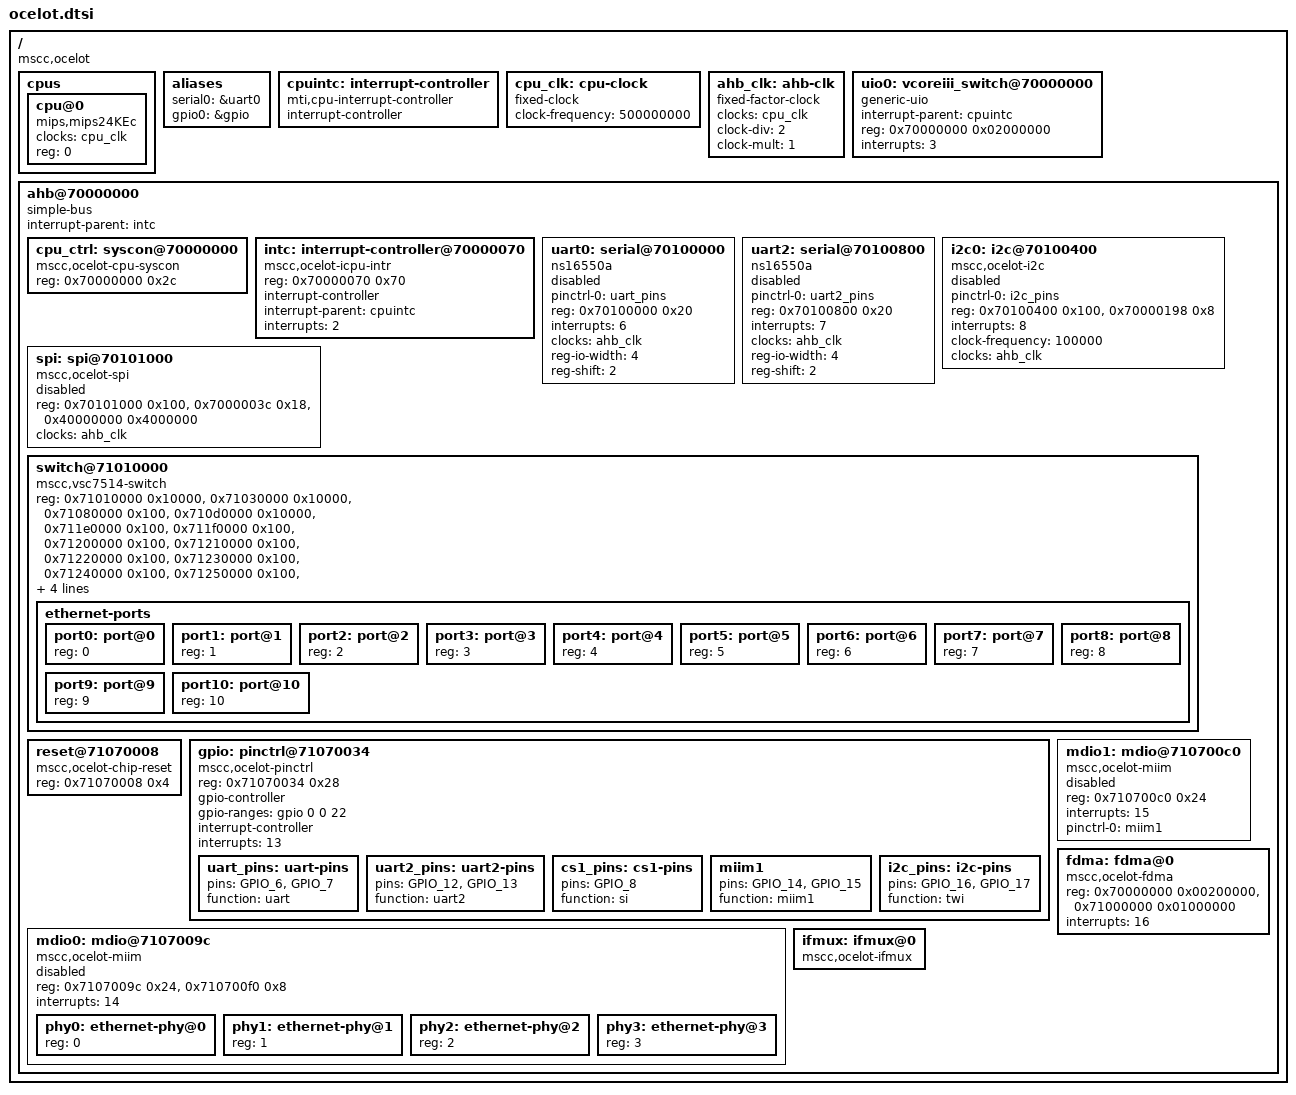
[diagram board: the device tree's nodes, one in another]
// SPDX-License-Identifier: (GPL-2.0 OR MIT)
/* Copyright (c) 2017 Microsemi Corporation */

/ {
	#address-cells = <1>;
	#size-cells = <1>;
	compatible = "mscc,ocelot";

	cpus {
		#address-cells = <1>;
		#size-cells = <0>;

		cpu@0 {
			compatible = "mips,mips24KEc";
			device_type = "cpu";
			clocks = <&cpu_clk>;
			reg = <0>;
		};
	};

	aliases {
		serial0 = &uart0;
		gpio0 = &gpio;
	};

	cpuintc: interrupt-controller {
		#address-cells = <0>;
		#interrupt-cells = <1>;
		interrupt-controller;
		compatible = "mti,cpu-interrupt-controller";
	};

	cpu_clk: cpu-clock {
		compatible = "fixed-clock";
		#clock-cells = <0>;
		clock-frequency = <500000000>;
	};

	ahb_clk: ahb-clk {
		compatible = "fixed-factor-clock";
		#clock-cells = <0>;
		clocks = <&cpu_clk>;
		clock-div = <2>;
		clock-mult = <1>;
	};

	uio0: vcoreiii_switch@70000000 {
		compatible = "generic-uio";
		interrupt-parent = <&cpuintc>;
		reg = <0x70000000 0x02000000>;
		reg-names = "origin1_2";
		interrupts = <3>;
	};

	ahb@70000000 {
		compatible = "simple-bus";
		#address-cells = <1>;
		#size-cells = <1>;
		ranges;

		interrupt-parent = <&intc>;

		cpu_ctrl: syscon@70000000 {
			compatible = "mscc,ocelot-cpu-syscon", "syscon";
			reg = <0x70000000 0x2c>;
		};

		intc: interrupt-controller@70000070 {
			compatible = "mscc,ocelot-icpu-intr";
			reg = <0x70000070 0x70>;
			#interrupt-cells = <1>;
			interrupt-controller;
			interrupt-parent = <&cpuintc>;
			interrupts = <2>;
		};

		uart0: serial@70100000 {
			pinctrl-0 = <&uart_pins>;
			pinctrl-names = "default";
			compatible = "ns16550a";
			reg = <0x70100000 0x20>;
			interrupts = <6>;
			clocks = <&ahb_clk>;
			reg-io-width = <4>;
			reg-shift = <2>;

			status = "disabled";
		};

		uart2: serial@70100800 {
			pinctrl-0 = <&uart2_pins>;
			pinctrl-names = "default";
			compatible = "ns16550a";
			reg = <0x70100800 0x20>;
			interrupts = <7>;
			clocks = <&ahb_clk>;
			reg-io-width = <4>;
			reg-shift = <2>;

			status = "disabled";
		};

		i2c0: i2c@70100400 {
			compatible = "mscc,ocelot-i2c", "snps,designware-i2c";
			status = "disabled";
			pinctrl-0 = <&i2c_pins>;
			pinctrl-names = "default";
			reg = <0x70100400 0x100>, <0x70000198 0x8>;
			#address-cells = <1>;
			#size-cells = <0>;
			interrupts = <8>;
			clock-frequency = <100000>;
			clocks = <&ahb_clk>;
		};

		spi: spi@70101000 {
			compatible = "mscc,ocelot-spi", "snps,dw-apb-ssi";
			#address-cells = <1>;
			#size-cells = <0>;
			reg = <0x70101000 0x100>, <0x7000003c 0x18>, <0x40000000 0x4000000>;
			clocks = <&ahb_clk>;

			status = "disabled";
		};

		switch@71010000 {
			compatible = "mscc,vsc7514-switch";
			reg = <0x71010000 0x10000>,
			      <0x71030000 0x10000>,
			      <0x71080000 0x100>,
			      <0x710d0000 0x10000>,
			      <0x711e0000 0x100>,
			      <0x711f0000 0x100>,
			      <0x71200000 0x100>,
			      <0x71210000 0x100>,
			      <0x71220000 0x100>,
			      <0x71230000 0x100>,
			      <0x71240000 0x100>,
			      <0x71250000 0x100>,
			      <0x71260000 0x100>,
			      <0x71270000 0x100>,
			      <0x71280000 0x100>,
			      <0x71800000 0x80000>,
			      <0x71880000 0x10000>;
			reg-names = "sys", "rew", "qs", "hsio", "port0",
				    "port1", "port2", "port3", "port4", "port5",
				    "port6", "port7", "port8", "port9", "port10",
				    "qsys", "ana";
			interrupts = <21 22>;
			interrupt-names = "xtr", "inj";

			ethernet-ports {
				#address-cells = <1>;
				#size-cells = <0>;

				port0: port@0 {
					reg = <0>;
				};
				port1: port@1 {
					reg = <1>;
				};
				port2: port@2 {
					reg = <2>;
				};
				port3: port@3 {
					reg = <3>;
				};
				port4: port@4 {
					reg = <4>;
				};
				port5: port@5 {
					reg = <5>;
				};
				port6: port@6 {
					reg = <6>;
				};
				port7: port@7 {
					reg = <7>;
				};
				port8: port@8 {
					reg = <8>;
				};
				port9: port@9 {
					reg = <9>;
				};
				port10: port@10 {
					reg = <10>;
				};
			};
		};

		reset@71070008 {
			compatible = "mscc,ocelot-chip-reset";
			reg = <0x71070008 0x4>;
		};

		gpio: pinctrl@71070034 {
			compatible = "mscc,ocelot-pinctrl";
			reg = <0x71070034 0x28>;
			gpio-controller;
			#gpio-cells = <2>;
			gpio-ranges = <&gpio 0 0 22>;
			interrupt-controller;
			interrupts = <13>;
			#interrupt-cells = <2>;

			uart_pins: uart-pins {
				pins = "GPIO_6", "GPIO_7";
				function = "uart";
			};

			uart2_pins: uart2-pins {
				pins = "GPIO_12", "GPIO_13";
				function = "uart2";
			};

			cs1_pins: cs1-pins {
				pins = "GPIO_8";
				function = "si";
			};

			miim1: miim1 {
				pins = "GPIO_14", "GPIO_15";
				function = "miim1";
			};

			i2c_pins: i2c-pins {
				pins = "GPIO_16", "GPIO_17";
				function = "twi";
			};
		};

		mdio0: mdio@7107009c {
			#address-cells = <1>;
			#size-cells = <0>;
			compatible = "mscc,ocelot-miim";
			reg = <0x7107009c 0x24>, <0x710700f0 0x8>;
			interrupts = <14>;
			status = "disabled";

			phy0: ethernet-phy@0 {
				reg = <0>;
			};
			phy1: ethernet-phy@1 {
				reg = <1>;
			};
			phy2: ethernet-phy@2 {
				reg = <2>;
			};
			phy3: ethernet-phy@3 {
				reg = <3>;
			};
		};

		mdio1: mdio@710700c0 {
			#address-cells = <1>;
			#size-cells = <0>;
			compatible = "mscc,ocelot-miim";
			reg = <0x710700c0 0x24>;
			interrupts = <15>;
			pinctrl-names = "default";
			pinctrl-0 = <&miim1>;
			status = "disabled";
		};

		fdma: fdma@0 {
			compatible = "mscc,ocelot-fdma";
			status = "okay";
			reg = <0x70000000 0x00200000>, <0x71000000 0x01000000>;
			interrupts = <16>;
		};

		ifmux: ifmux@0 {
			compatible = "mscc,ocelot-ifmux";
			status = "okay";
		};
	};
};
